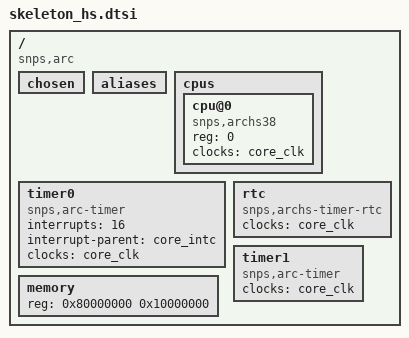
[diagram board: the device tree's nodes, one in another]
/ {
	compatible = "snps,arc";
	#address-cells = <1>;
	#size-cells = <1>;
	chosen { };
	aliases { };
	cpus {
		#address-cells = <1>;
		#size-cells = <0>;
		cpu@0 {
			device_type = "cpu";
			compatible = "snps,archs38";
			reg = <0>;
			clocks = <&core_clk>;
		};
	};
	timer0 {
		compatible = "snps,arc-timer";
		interrupts = <16>;
		interrupt-parent = <&core_intc>;
		clocks = <&core_clk>;
	};
	rtc {
		compatible = "snps,archs-timer-rtc";
		clocks = <&core_clk>;
	};
	timer1 {
		compatible = "snps,arc-timer";
		clocks = <&core_clk>;
	};
	memory {
		device_type = "memory";
		reg = <0x80000000 0x10000000>;	 
	};
};
